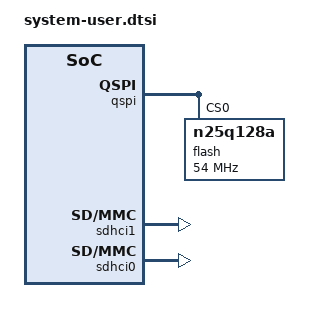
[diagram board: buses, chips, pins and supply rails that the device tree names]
/include/ "system-conf.dtsi"
/ {
    chosen {
        bootargs = "earlycon console=ttyPS0,115200 clk_ignore_unused cpuidle.off=1 root=/dev/mmcblk1p2 rw rootwait";
        stdout-path = "serial0:115200n8";
    };

    reserved-memory {
        #address-cells = <2>;
        #size-cells = <2>;
        ranges;
        reserved_for_fpga: map_fpga@40000000{
            no-map;
            reg = <0x0 0x40000000 0x0 0x40000000 0x0 0xb0000000 0x0 0x1000>;
        };
    };
    fpga-driver@0{
        status = "okay";
        compatible = "xlnx,fpga_zu9";
        memory-region = <&reserved_for_fpga>;
        interrupt-parent = <&gic>;
        interrupts = <0 89 4>, <0 90 4>;    //89-tlk2711B-recv, 90-tlk2711A-send
    };
    
    xlnk {
        compatible = "xlnk,xlnk-1.0";
    };
};

&qspi {
    flash@0 {
        compatible = "n25q128a","micron,m25p80";
        #address-cells = <1>;
        #size-cells = <1>;
        reg = <0x0 0xff0f0000 0x10000000>;
        spi-tx-bus-width = <1>;
        spi-rx-bus-width = <4>; /* FIXME also DUAL configuration possible */
        spi-max-frequency = <54000000>; /* Based on DC1 spec */
    };
};


&sdhci1 {
    status = "okay";
    disable-wp;
    no-1-8-v;
};

&sdhci0 {
    status="okay";
    no-1-8-v;
};

